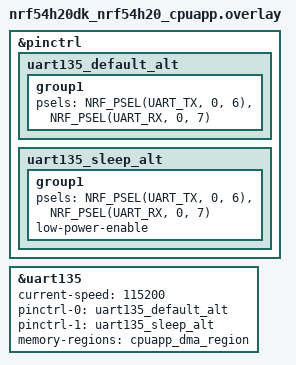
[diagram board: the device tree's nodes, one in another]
/*
 * Copyright (c) 2024 Nordic Semiconductor ASA
 *
 * SPDX-License-Identifier: Apache-2.0
 */

&pinctrl {
	uart135_default_alt: uart135_default_alt {
		group1 {
			psels = <NRF_PSEL(UART_TX, 0, 6)>,
				<NRF_PSEL(UART_RX, 0, 7)>;
		};
	};

	uart135_sleep_alt: uart135_sleep_alt {
		group1 {
			psels = <NRF_PSEL(UART_TX, 0, 6)>,
				<NRF_PSEL(UART_RX, 0, 7)>;
			low-power-enable;
		};
	};
};

dut: &uart135 {
	status = "okay";
	current-speed = <115200>;
	pinctrl-0 = <&uart135_default_alt>;
	pinctrl-1 = <&uart135_sleep_alt>;
	pinctrl-names = "default", "sleep";
	memory-regions = <&cpuapp_dma_region>;
};
